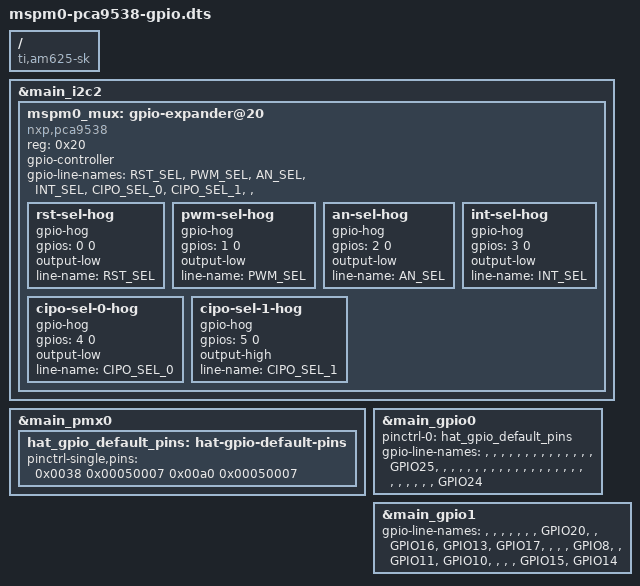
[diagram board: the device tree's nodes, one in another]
/dts-v1/;
/plugin/;

/ {
	compatible = "ti,am625-sk", "ti,am625";

	fragment@0 {
		/* SK-AM62 40-pin expansion header I2C is the SoC I2C2 bus. */
		target = <&main_i2c2>;
		__overlay__ {
			#address-cells = <1>;
			#size-cells = <0>;

			mspm0_mux: gpio-expander@20 {
				compatible = "nxp,pca9538";
				reg = <0x20>;
				gpio-controller;
				#gpio-cells = <2>;
				gpio-line-names =
					"RST_SEL",
					"PWM_SEL",
					"AN_SEL",
					"INT_SEL",
					"CIPO_SEL_0",
					"CIPO_SEL_1",
					"",
					"";
				status = "okay";

				/* TI AM62 SK-EVM audio-board routing defaults. */
				rst-sel-hog {
					gpio-hog;
					gpios = <0 0>;
					output-low;
					line-name = "RST_SEL";
				};

				pwm-sel-hog {
					gpio-hog;
					gpios = <1 0>;
					output-low;
					line-name = "PWM_SEL";
				};

				an-sel-hog {
					gpio-hog;
					gpios = <2 0>;
					output-low;
					line-name = "AN_SEL";
				};

				int-sel-hog {
					gpio-hog;
					gpios = <3 0>;
					output-low;
					line-name = "INT_SEL";
				};

				cipo-sel-0-hog {
					gpio-hog;
					gpios = <4 0>;
					output-low;
					line-name = "CIPO_SEL_0";
				};

				cipo-sel-1-hog {
					gpio-hog;
					gpios = <5 0>;
					output-high;
					line-name = "CIPO_SEL_1";
				};
			};
		};
	};

	fragment@1 {
		target = <&main_pmx0>;
		__overlay__ {
			hat_gpio_default_pins: hat-gpio-default-pins {
				pinctrl-single,pins = <
					0x0038 0x00050007 /* HAT pin 22 / GPIO25 / GPIO0_14 input */
					0x00a0 0x00050007 /* HAT pin 18 / GPIO24 / GPIO0_39 input */
				>;
			};
		};
	};

	fragment@2 {
		target = <&main_gpio0>;
		__overlay__ {
			pinctrl-names = "default";
			pinctrl-0 = <&hat_gpio_default_pins>;
			gpio-line-names = "", "", "", "", "", "", "", "", "", "",
				"", "", "", "", "GPIO25", "", "", "", "", "",
				"", "", "", "", "", "", "", "", "", "",
				"", "", "", "", "", "", "", "", "", "GPIO24";
			status = "okay";
		};
	};

	fragment@3 {
		target = <&main_gpio1>;
		__overlay__ {
			gpio-line-names = "", "", "", "", "", "", "", "GPIO20",
				"", "GPIO16", "GPIO13", "GPIO17", "", "", "",
				"GPIO8", "", "GPIO11", "GPIO10", "", "", "",
				"GPIO15", "GPIO14";
			status = "okay";
		};
	};
};
